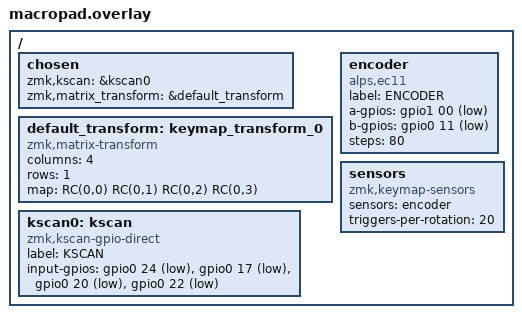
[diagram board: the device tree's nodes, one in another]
/*
 * Pinout keuzes (SuperMini nRF52840):
 *
 * Switch 1  → P0.17
 * Switch 2  → P0.20
 * Switch 3  → P0.22
 *
 * Encoder A (CLK) → P1.00
 * Encoder B (DT)  → P0.11
 * Encoder SW      → P0.24
 *
 * Alle switches zijn direct gewired (geen matrix), met interne pull-up.
 */

#include <dt-bindings/zmk/matrix_transform.h>

/ {
    chosen {
        zmk,kscan = &kscan0;
        zmk,matrix_transform = &default_transform;
    };

    default_transform: keymap_transform_0 {
        compatible = "zmk,matrix-transform";
        columns = <4>;
        rows = <1>;

        /* volgorde: encoder_sw, switch1, switch2, switch3 */
        map = <
            RC(0,0) RC(0,1) RC(0,2) RC(0,3)
        >;
    };

    kscan0: kscan {
        compatible = "zmk,kscan-gpio-direct";
        label = "KSCAN";

        input-gpios
            = <&gpio0 24 (GPIO_ACTIVE_LOW | GPIO_PULL_UP)>   /* encoder knop P0.24 */
            , <&gpio0 17 (GPIO_ACTIVE_LOW | GPIO_PULL_UP)>   /* switch 1     P0.17 */
            , <&gpio0 20 (GPIO_ACTIVE_LOW | GPIO_PULL_UP)>   /* switch 2     P0.20 */
            , <&gpio0 22 (GPIO_ACTIVE_LOW | GPIO_PULL_UP)>   /* switch 3     P0.22 */
            ;
    };

    encoder: encoder {
        compatible = "alps,ec11";
        label = "ENCODER";
        a-gpios = <&gpio1 00 (GPIO_ACTIVE_LOW | GPIO_PULL_UP)>;
        b-gpios = <&gpio0 11 (GPIO_ACTIVE_LOW | GPIO_PULL_UP)>;
        steps = <80>;
        status = "okay";
    };

    sensors {
        compatible = "zmk,keymap-sensors";
        sensors = <&encoder>;
        triggers-per-rotation = <20>;
    };
};
